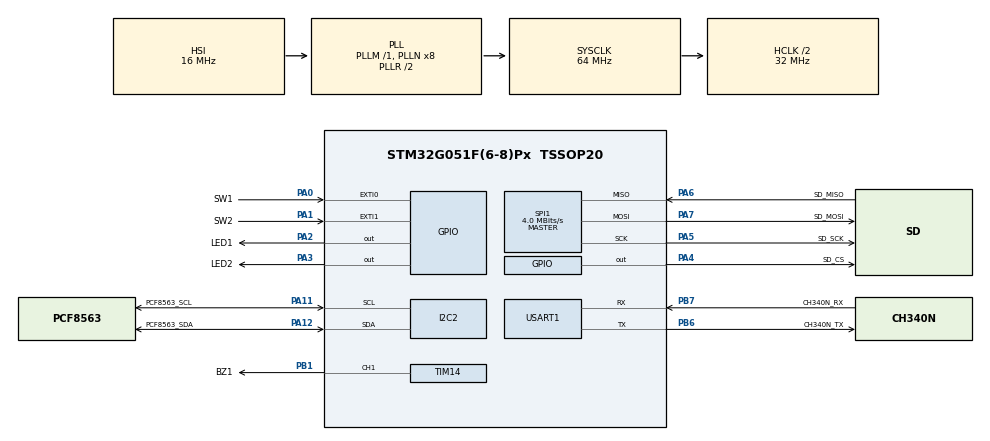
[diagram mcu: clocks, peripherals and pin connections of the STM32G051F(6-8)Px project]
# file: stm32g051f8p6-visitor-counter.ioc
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FATFS._MAX_SS=4096
FATFS._USE_LABEL=0
FATFS._USE_LFN=1
I2C2.Timing=0x00503D58
Mcu.Family=STM32G0
Mcu.Name=STM32G051F(6-8)Px
Mcu.Package=TSSOP20
NVIC.EXTI0_1_IRQn=true\:0\:0\:false\:false\:true\:true\:true\:true
NVIC.USART1_IRQn=true\:0\:0\:false\:false\:true\:true\:true\:true
PA0.GPIO_Label=SW1
PA0.GPIO_PuPd=GPIO_PULLUP
PA0.Signal=GPXTI0
PA1.GPIO_Label=SW2
PA1.GPIO_PuPd=GPIO_PULLUP
PA1.Signal=GPXTI1
PA11\ [PA9].GPIO_Label=PCF8563_SCL
PA11\ [PA9].Mode=I2C
PA11\ [PA9].Signal=I2C2_SCL
PA12\ [PA10].GPIO_Label=PCF8563_SDA
PA12\ [PA10].Mode=I2C
PA12\ [PA10].Signal=I2C2_SDA
PA13.Mode=Serial_Wire
PA13.Signal=SYS_SWDIO
PA14-BOOT0.Mode=Serial_Wire
PA14-BOOT0.Signal=SYS_SWCLK
PA14-BOOT0__PA15.StandardMode=true
PA2.GPIO_Label=LED1
PA2.Signal=GPIO_Output
PA3.GPIO_Label=LED2
PA3.Signal=GPIO_Output
PA4.GPIO_Label=SD_CS
PA4.GPIO_PuPd=GPIO_PULLUP
PA4.GPIO_Speed=GPIO_SPEED_FREQ_VERY_HIGH
PA4.PinState=GPIO_PIN_SET
PA4.Signal=GPIO_Output
PA5.GPIO_Label=SD_SCK
PA5.GPIO_Speed=GPIO_SPEED_FREQ_HIGH
PA5.Mode=Full_Duplex_Master
PA5.Signal=SPI1_SCK
PA6.GPIO_Label=SD_MISO
PA6.GPIO_Speed=GPIO_SPEED_FREQ_HIGH
PA6.Mode=Full_Duplex_Master
PA6.Signal=SPI1_MISO
PA7.GPIO_Label=SD_MOSI
PA7.GPIO_Speed=GPIO_SPEED_FREQ_HIGH
PA7.Mode=Full_Duplex_Master
PA7.Signal=SPI1_MOSI
PB0__PB1__PB2__PA8.StandardMode=true
PB1.GPIO_Label=BZ1
PB1.Signal=S_TIM14_CH1
PB3__PB4__PB5__PB6.StandardMode=true
PB6.GPIO_Label=CH340N_TX
PB6.GPIO_PuPd=GPIO_PULLUP
PB6.Mode=Asynchronous
PB6.Signal=USART1_TX
PB7.GPIO_Label=CH340N_RX
PB7.GPIO_PuPd=GPIO_PULLUP
PB7.Mode=Asynchronous
PB7.Signal=USART1_RX
PB7__PB8.StandardMode=true
PC14-OSC32_IN\ (PC14)__PB9.StandardMode=true
ProjectManager.HeapSize=0x200
ProjectManager.StackSize=0x400
ProjectManager.TargetToolchain=CMake
RCC.ADCFreq_Value=64000000
RCC.AHBCLKDivider=RCC_SYSCLK_DIV2
RCC.AHBFreq_Value=32000000
RCC.CortexFreq_Value=32000000
RCC.EXTERNAL_CLOCK_VALUE=48000
RCC.HCLKFreq_Value=32000000
RCC.HSE_VALUE=8000000
RCC.HSI_VALUE=16000000
RCC.LSE_VALUE=32768
RCC.SYSCLKFreq_VALUE=64000000
RCC.SYSCLKSource=RCC_SYSCLKSOURCE_PLLCLK
RCC.VCOOutputFreq_Value=128000000
SH.S_TIM14_CH1.0=TIM14_CH1,PWM Generation1 CH1
SPI1.BaudRatePrescaler=SPI_BAUDRATEPRESCALER_8
SPI1.CLKPhase=SPI_PHASE_2EDGE
SPI1.CLKPolarity=SPI_POLARITY_HIGH
SPI1.CRCCalculation=SPI_CRCCALCULATION_DISABLE
SPI1.CalculateBaudRate=4.0 MBits/s
SPI1.Direction=SPI_DIRECTION_2LINES
SPI1.Mode=SPI_MODE_MASTER
SPI1.VirtualType=VM_MASTER
TIM14.Channel=TIM_CHANNEL_1
TIM14.Period=63999
TIM14.Prescaler=2
TIM14.Pulse=31999
USART1.VirtualMode-Asynchronous=VM_ASYNC
VP_FATFS_VS_Generic.Mode=User_defined
VP_SYS_VS_DBSignals.Mode=DisableDeadBatterySignals
VP_TIM14_VS_ClockSourceINT.Mode=Enable_Timer
board=custom

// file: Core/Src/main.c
/* USER CODE BEGIN Header */
/**
  ******************************************************************************
  * @file           : main.c
  * @brief          : Main program body
  ******************************************************************************
  * @attention
  *
  * Copyright (c) 2026 STMicroelectronics.
  * All rights reserved.
  *
  * This software is licensed under terms that can be found in the LICENSE file
  * in the root directory of this software component.
  * If no LICENSE file comes with this software, it is provided AS-IS.
  *
  ******************************************************************************
  */
/* USER CODE END Header */
#include "main.h"
#include "app_fatfs.h"

/* USER CODE BEGIN Includes */

#include "app_main.h"

/* USER CODE END Includes */

I2C_HandleTypeDef hi2c2;

SPI_HandleTypeDef hspi1;

TIM_HandleTypeDef htim14;

UART_HandleTypeDef huart1;

void SystemClock_Config(void);
static void MX_GPIO_Init(void);
static void MX_I2C2_Init(void);
static void MX_SPI1_Init(void);
static void MX_TIM14_Init(void);
static void MX_USART1_UART_Init(void);

int main(void)
{

  /* MCU Configuration--------------------------------------------------------*/

  /* Reset of all peripherals, Initializes the Flash interface and the Systick. */
  HAL_Init();

  /* Configure the system clock */
  SystemClock_Config();

  /* Initialize all configured peripherals */
  MX_GPIO_Init();
  MX_I2C2_Init();
  MX_SPI1_Init();
  MX_TIM14_Init();
  MX_USART1_UART_Init();
  if (MX_FATFS_Init() != APP_OK) {
    Error_Handler();
  }
  /* USER CODE BEGIN 2 */

  app_setup();

  /* USER CODE END 2 */

  /* Infinite loop */
  while (1)
  {

    /* USER CODE BEGIN 3 */

    app_loop();

  }
  /* USER CODE END 3 */
}

void SystemClock_Config(void)
{
  RCC_OscInitTypeDef RCC_OscInitStruct = {0};
  RCC_ClkInitTypeDef RCC_ClkInitStruct = {0};

  /** Configure the main internal regulator output voltage
  */
  HAL_PWREx_ControlVoltageScaling(PWR_REGULATOR_VOLTAGE_SCALE1);

  /** Initializes the RCC Oscillators according to the specified parameters
  * in the RCC_OscInitTypeDef structure.
  */
  RCC_OscInitStruct.OscillatorType = RCC_OSCILLATORTYPE_HSI;
  RCC_OscInitStruct.HSIState = RCC_HSI_ON;
  RCC_OscInitStruct.HSIDiv = RCC_HSI_DIV1;
  RCC_OscInitStruct.HSICalibrationValue = RCC_HSICALIBRATION_DEFAULT;
  RCC_OscInitStruct.PLL.PLLState = RCC_PLL_ON;
  RCC_OscInitStruct.PLL.PLLSource = RCC_PLLSOURCE_HSI;
  RCC_OscInitStruct.PLL.PLLM = RCC_PLLM_DIV1;
  RCC_OscInitStruct.PLL.PLLN = 8;
  RCC_OscInitStruct.PLL.PLLP = RCC_PLLP_DIV2;
  RCC_OscInitStruct.PLL.PLLQ = RCC_PLLQ_DIV2;
  RCC_OscInitStruct.PLL.PLLR = RCC_PLLR_DIV2;
  if (HAL_RCC_OscConfig(&RCC_OscInitStruct) != HAL_OK)
  {
    Error_Handler();
  }

  /** Initializes the CPU, AHB and APB buses clocks
  */
  RCC_ClkInitStruct.ClockType = RCC_CLOCKTYPE_HCLK|RCC_CLOCKTYPE_SYSCLK
                              |RCC_CLOCKTYPE_PCLK1;
  RCC_ClkInitStruct.SYSCLKSource = RCC_SYSCLKSOURCE_PLLCLK;
  RCC_ClkInitStruct.AHBCLKDivider = RCC_SYSCLK_DIV2;
  RCC_ClkInitStruct.APB1CLKDivider = RCC_HCLK_DIV1;

  if (HAL_RCC_ClockConfig(&RCC_ClkInitStruct, FLASH_LATENCY_1) != HAL_OK)
  {
    Error_Handler();
  }
}

static void MX_I2C2_Init(void)
{

  hi2c2.Instance = I2C2;
  hi2c2.Init.Timing = 0x00503D58;
  hi2c2.Init.OwnAddress1 = 0;
  hi2c2.Init.AddressingMode = I2C_ADDRESSINGMODE_7BIT;
  hi2c2.Init.DualAddressMode = I2C_DUALADDRESS_DISABLE;
  hi2c2.Init.OwnAddress2 = 0;
  hi2c2.Init.OwnAddress2Masks = I2C_OA2_NOMASK;
  hi2c2.Init.GeneralCallMode = I2C_GENERALCALL_DISABLE;
  hi2c2.Init.NoStretchMode = I2C_NOSTRETCH_DISABLE;
  if (HAL_I2C_Init(&hi2c2) != HAL_OK)
  {
    Error_Handler();
  }

  /** Configure Analogue filter
  */
  if (HAL_I2CEx_ConfigAnalogFilter(&hi2c2, I2C_ANALOGFILTER_ENABLE) != HAL_OK)
  {
    Error_Handler();
  }

  /** Configure Digital filter
  */
  if (HAL_I2CEx_ConfigDigitalFilter(&hi2c2, 0) != HAL_OK)
  {
    Error_Handler();
  }

}

static void MX_SPI1_Init(void)
{

  /* SPI1 parameter configuration*/
  hspi1.Instance = SPI1;
  hspi1.Init.Mode = SPI_MODE_MASTER;
  hspi1.Init.Direction = SPI_DIRECTION_2LINES;
  hspi1.Init.DataSize = SPI_DATASIZE_8BIT;
  hspi1.Init.CLKPolarity = SPI_POLARITY_HIGH;
  hspi1.Init.CLKPhase = SPI_PHASE_2EDGE;
  hspi1.Init.NSS = SPI_NSS_SOFT;
  hspi1.Init.BaudRatePrescaler = SPI_BAUDRATEPRESCALER_8;
  hspi1.Init.FirstBit = SPI_FIRSTBIT_MSB;
  hspi1.Init.TIMode = SPI_TIMODE_DISABLE;
  hspi1.Init.CRCCalculation = SPI_CRCCALCULATION_DISABLE;
  hspi1.Init.CRCPolynomial = 7;
  hspi1.Init.CRCLength = SPI_CRC_LENGTH_DATASIZE;
  hspi1.Init.NSSPMode = SPI_NSS_PULSE_DISABLE;
  if (HAL_SPI_Init(&hspi1) != HAL_OK)
  {
    Error_Handler();
  }

}

static void MX_TIM14_Init(void)
{

  TIM_OC_InitTypeDef sConfigOC = {0};

  htim14.Instance = TIM14;
  htim14.Init.Prescaler = 2;
  htim14.Init.CounterMode = TIM_COUNTERMODE_UP;
  htim14.Init.Period = 63999;
  htim14.Init.ClockDivision = TIM_CLOCKDIVISION_DIV1;
  htim14.Init.AutoReloadPreload = TIM_AUTORELOAD_PRELOAD_DISABLE;
  if (HAL_TIM_Base_Init(&htim14) != HAL_OK)
  {
    Error_Handler();
  }
  if (HAL_TIM_PWM_Init(&htim14) != HAL_OK)
  {
    Error_Handler();
  }
  sConfigOC.OCMode = TIM_OCMODE_PWM1;
  sConfigOC.Pulse = 31999;
  sConfigOC.OCPolarity = TIM_OCPOLARITY_HIGH;
  sConfigOC.OCFastMode = TIM_OCFAST_DISABLE;
  if (HAL_TIM_PWM_ConfigChannel(&htim14, &sConfigOC, TIM_CHANNEL_1) != HAL_OK)
  {
    Error_Handler();
  }
  HAL_TIM_MspPostInit(&htim14);

}

static void MX_USART1_UART_Init(void)
{

  huart1.Instance = USART1;
  huart1.Init.BaudRate = 115200;
  huart1.Init.WordLength = UART_WORDLENGTH_8B;
  huart1.Init.StopBits = UART_STOPBITS_1;
  huart1.Init.Parity = UART_PARITY_NONE;
  huart1.Init.Mode = UART_MODE_TX_RX;
  huart1.Init.HwFlowCtl = UART_HWCONTROL_NONE;
  huart1.Init.OverSampling = UART_OVERSAMPLING_16;
  huart1.Init.OneBitSampling = UART_ONE_BIT_SAMPLE_DISABLE;
  huart1.Init.ClockPrescaler = UART_PRESCALER_DIV1;
  huart1.AdvancedInit.AdvFeatureInit = UART_ADVFEATURE_NO_INIT;
  if (HAL_UART_Init(&huart1) != HAL_OK)
  {
    Error_Handler();
  }
  if (HAL_UARTEx_SetTxFifoThreshold(&huart1, UART_TXFIFO_THRESHOLD_1_8) != HAL_OK)
  {
    Error_Handler();
  }
  if (HAL_UARTEx_SetRxFifoThreshold(&huart1, UART_RXFIFO_THRESHOLD_1_8) != HAL_OK)
  {
    Error_Handler();
  }
  if (HAL_UARTEx_DisableFifoMode(&huart1) != HAL_OK)
  {
    Error_Handler();
  }

}

static void MX_GPIO_Init(void)
{
  GPIO_InitTypeDef GPIO_InitStruct = {0};

  /* GPIO Ports Clock Enable */
  __HAL_RCC_GPIOB_CLK_ENABLE();
  __HAL_RCC_GPIOA_CLK_ENABLE();

  /*Configure GPIO pin Output Level */
  HAL_GPIO_WritePin(GPIOA, LED1_Pin|LED2_Pin, GPIO_PIN_RESET);

  /*Configure GPIO pin Output Level */
  HAL_GPIO_WritePin(SD_CS_GPIO_Port, SD_CS_Pin, GPIO_PIN_SET);

  /*Configure GPIO pins : SW1_Pin SW2_Pin */
  GPIO_InitStruct.Pin = SW1_Pin|SW2_Pin;
  GPIO_InitStruct.Mode = GPIO_MODE_IT_RISING;
  GPIO_InitStruct.Pull = GPIO_PULLUP;
  HAL_GPIO_Init(GPIOA, &GPIO_InitStruct);

  /*Configure GPIO pins : LED1_Pin LED2_Pin */
  GPIO_InitStruct.Pin = LED1_Pin|LED2_Pin;
  GPIO_InitStruct.Mode = GPIO_MODE_OUTPUT_PP;
  GPIO_InitStruct.Pull = GPIO_NOPULL;
  GPIO_InitStruct.Speed = GPIO_SPEED_FREQ_LOW;
  HAL_GPIO_Init(GPIOA, &GPIO_InitStruct);

  /*Configure GPIO pin : SD_CS_Pin */
  GPIO_InitStruct.Pin = SD_CS_Pin;
  GPIO_InitStruct.Mode = GPIO_MODE_OUTPUT_PP;
  GPIO_InitStruct.Pull = GPIO_PULLUP;
  GPIO_InitStruct.Speed = GPIO_SPEED_FREQ_VERY_HIGH;
  HAL_GPIO_Init(SD_CS_GPIO_Port, &GPIO_InitStruct);

  /* EXTI interrupt init*/
  HAL_NVIC_SetPriority(EXTI0_1_IRQn, 0, 0);
  HAL_NVIC_EnableIRQ(EXTI0_1_IRQn);

}

/* USER CODE BEGIN 4 */

void HAL_GPIO_EXTI_Rising_Callback(uint16_t GPIO_Pin)
{
  app_gpio_rising(GPIO_Pin);
}

void HAL_UART_RxCpltCallback(UART_HandleTypeDef* huart)
{
  app_uart_rx_complete(huart);
}

/* USER CODE END 4 */

void Error_Handler(void)
{
  __disable_irq();
  while (1)
  {
  }
}
